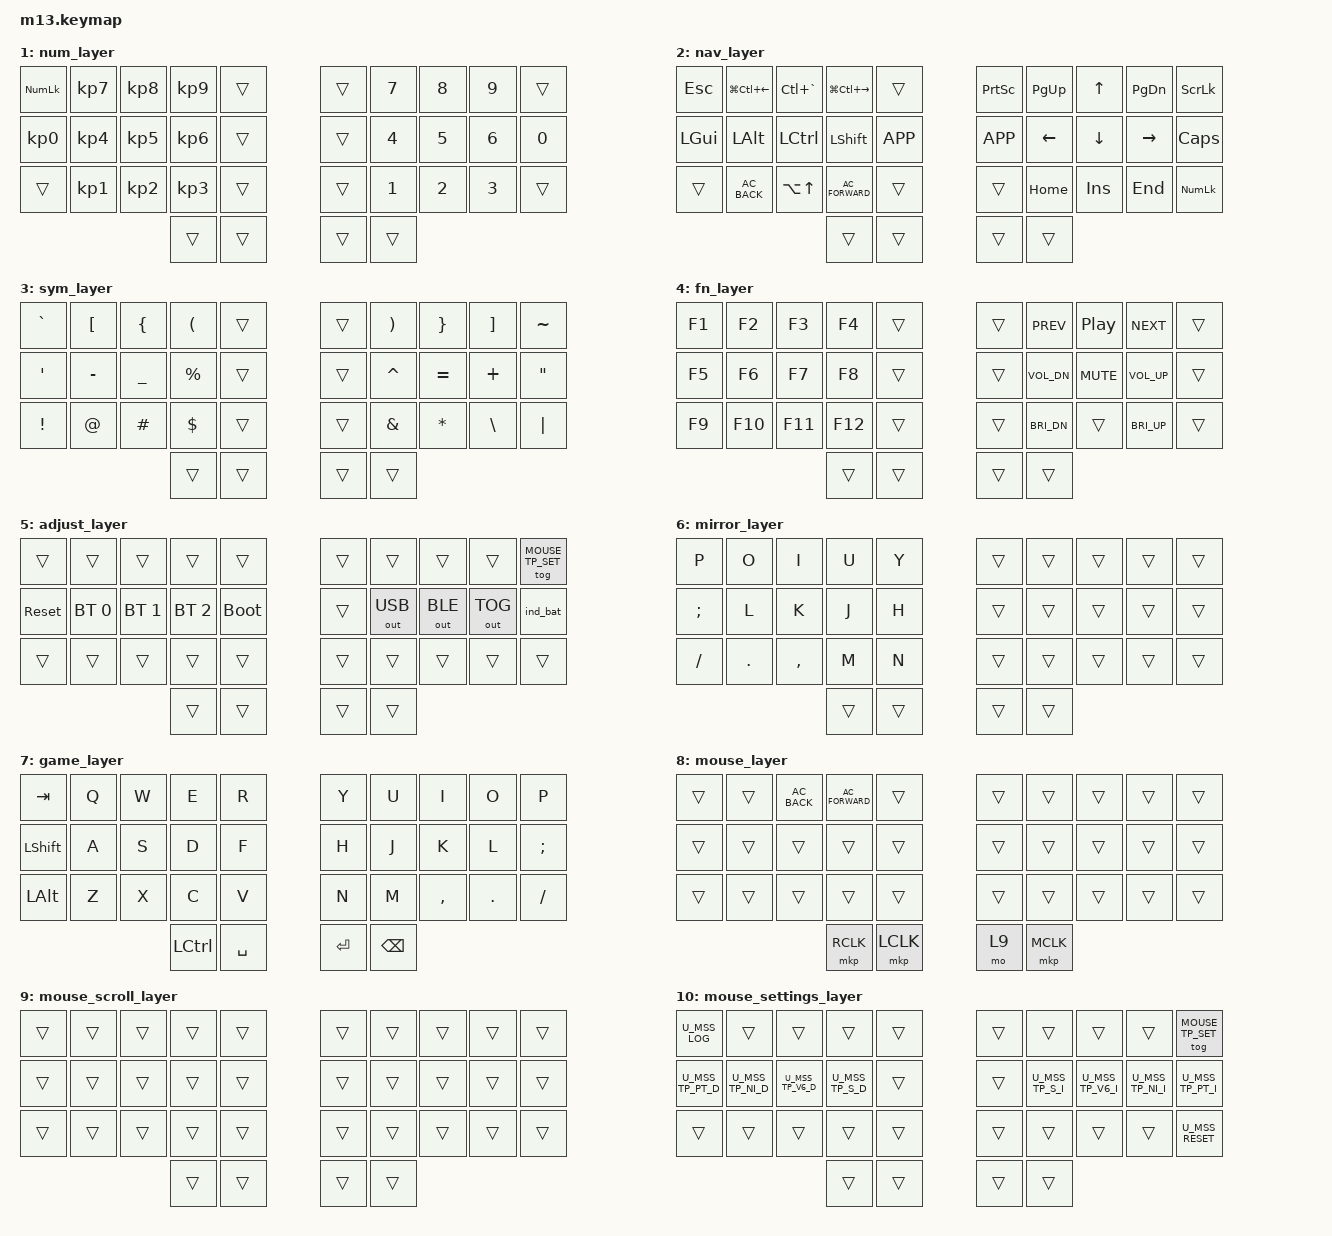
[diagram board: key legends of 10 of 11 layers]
#include <behaviors.dtsi>
#include <behaviors/status_led.dtsi>
#include <dt-bindings/zmk/keys.h>
#include <dt-bindings/zmk/bt.h>
#include <dt-bindings/zmk/outputs.h>
#include <dt-bindings/zmk/ext_power.h>


#define HAS_MOUSE_KEYS
#define HAS_MOUSE_TP

#ifdef HAS_MOUSE_KEYS
  #include <dt-bindings/zmk/mouse.h>
  #include <behaviors/mouse_keys.dtsi>
#endif  // HAS_MOUSE_KEYS

#ifdef HAS_MOUSE_TP
    #define MOUSE_TP 8
    #define MOUSE_TP_SCROLL 9 // not used
    #define MOUSE_TP_SET 10
    #define U_TOG_TP_SET &tog MOUSE_TP_SET
    #include <trackpoint/keymap.dtsi>

    #ifdef MOUSE_PS2_DT_PRESENT
    // Static trackpoint tuning (see the zmk-trackpoint README for all options)
    &mouse_ps2 {
        // How sensitive the TP is (Default: 128 / Max: 255)
        tp-sensitivity = <127>;

        // The maximum speed the TP will accelerate to (Default: 97 / Max: 255)
        tp-val6-upper-speed = <97>;

        // Sampling rate in hz. Allowed: 10,20,40,60,80,100,200
        sampling-rate = <100>;
    };
    #endif  // MOUSE_PS2_DT_PRESENT
#else
    #define MOUSE_TP 0
    #define U_TOG_TP_SET &none
#endif  // HAS_MOUSE_TP


#define HRML(k1,k2,k3,k4) &mt LGUI k1  &mt LALT k2  &mt LCTRL k3  &mt LSHFT k4
#define HRMR(k1,k2,k3,k4) &mt RSHFT k1  &mt RCTRL k2  &mt RALT k3  &mt RGUI k4
#define TERM &kp LC(GRAVE)
#define TASK_V &kp LG(TAB)
#define DESK_P &kp LG(LC(LEFT))
#define DESK_N &kp LG(LC(RIGHT))
#define COMBO(NAME, BINDINGS, KEYPOS, LAYERS) \
    combo_##NAME { \
        timeout-ms = <50>; \
        bindings = <BINDINGS>; \
        key-positions = <KEYPOS>; \
        layers = <LAYERS>; \
    };


&lt {
    flavor = "tap-preferred";
    tapping-term-ms = <150>;
    quick-tap-ms = <200>;
};

&mt {
    flavor = "balanced";
    tapping-term-ms = <150>;
    quick-tap-ms = <200>;
};


/ {
    //╭──────┬──────┬──────┬──────┬──────╮   ╭──────┬──────┬──────┬──────┬──────╮
    //│  0   │  1   │  2   │  3   │  4   │   │  5   │  6   │  7   │  8   │  9   │
    //├──────┼──────┼──────┼──────┼──────┼───┼──────┼──────┼──────┼──────┼──────┤
    //│  10  │  11  │  12  │  13  │  14  │   │  15  │  16  │  17  │  18  │  19  │
    //├──────┼──────┼──────┼──────┼──────┤   ├──────┼──────┼──────┼──────┼──────┤
    //│  20  │  21  │  22  │  23  │  24  │   │  25  │  26  │  27  │  28  │  29  │
    //╰──────┴──────┴──────┼──────┼──────┼───┼──────┼──────┼──────┴──────┴──────╯
    //                     |  30  |  31  |   |  32  |  33  |
    //                     ╰──────┴──────╯   ╰──────┴──────╯
    combos {
        compatible = "zmk,combos";
    // main
        COMBO(enter,              &kp RET,          12 13,        0)
        COMBO(backspace,          &kp BSPC,         11 12,        0)
        COMBO(delete,             &kp DEL,          11 13,        0)
        COMBO(fn_layer,           &mo 4,            30 24,        0)
        COMBO(go_up,              &kp LA(UP),        2  3,        8)
        COMBO(mouse_layer_lt,     &mo 8,            10 11,        0)
        COMBO(mouse_layer_rt,     &mo 8,            18 19,        0)
    // game
        COMBO(game,               &tog 7,           20 31,      0 7)
    // num
        COMBO(num_space_l,        &kp SPACE,        12 13,        1)
        COMBO(num_dot_l,          &kp DOT,          11 12,        1)
        COMBO(num_comma_l,        &kp COMMA,        11 13,        1)
        COMBO(num_space_r,        &kp SPACE,        16 17,        1)
        COMBO(num_dot_r,          &kp DOT,          17 18,        1)
        COMBO(num_comma_r,        &kp COMMA,        16 18,        1)
    // nav
        COMBO(nav_taskv,          TASK_V,            1  3,        2)
            // mirror
        COMBO(right_mirror,       &mo 6,             30 31,       0)
    // adjust
        COMBO(bluetooth_clear,    &bt BT_CLR,        10 14,       5)
    };


    conditional_layers {
        compatible = "zmk,conditional-layers";
        adjust_layer {
            if-layers = <2 3>;
            then-layer = <5>;
        };
    };


	chosen {
		zephyr,console = &cdc_acm_uart;
	};


    keymap {
        compatible = "zmk,keymap";

        // - 0
        default_layer {
            bindings = <
        //╭──────────┬──────────┬──────────┬──────────┬──────────╮   ╭──────────┬──────────┬──────────┬──────────┬──────────╮
        //│  Q       │  W       │  E       │  R       │  T       │   │  Y       │  U       │  I       │  O       │  P       │
            &kp Q      &lt 8 W    &kp E      &kp R      &kp T          &kp Y      &kp U      &kp I      &lt 8 O    &kp P
        //├──────────┼──────────┼──────────┼──────────┼──────────┤   ├──────────┼──────────┼──────────┼──────────┼──────────┤
        //│  A       │  S       │  D       │  F       │  G       │   │  H       │  J       │  K       │  L       │  ;       │
             HRML(A,        S,         D,         F)     &kp G          &kp H      HRMR(J,        K,         L,        SEMI)
        //├──────────┼──────────┼──────────┼──────────┼──────────┤   ├──────────┼──────────┼──────────┼──────────┼──────────┤
        //│  Z       │  X       │  C       │  V       │  B       │   │  N       │  M       │ , <      │ . >      │ / ?      │
            &kp Z      &kp X      &kp C      &kp V      &kp B          &kp N      &kp M      &kp COMMA  &kp DOT    &kp FSLH
        //╰──────────┴──────────┴──────────┼──────────┼──────────┤   ├──────────┼──────────┼──────────┴──────────┴──────────╯
                                            &lt 1 TAB  &lt 2 SPACE    &lt 3 RET  &lt 4 BSPC
        //                                 ╰──────────┴──────────╯   ╰──────────┴──────────╯
            >;
        };


        // - 1
        num_layer {
            bindings = <
        //╭──────────┬──────────┬──────────┬──────────┬──────────╮   ╭──────────┬──────────┬──────────┬──────────┬──────────╮
        //│  NLCK    │  7       │  8       │  9       │          │   │          │  7       │  8       │  9       │          │
            &kp KP_NUM &kp KP_N7  &kp KP_N8  &kp KP_N9  &trans         &trans     &kp N7     &kp N8     &kp N9     &trans
        //├──────────┼──────────┼──────────┼──────────┼──────────┤   ├──────────┼──────────┼──────────┼──────────┼──────────┤
        //│  0       │  4       │  5       │  6       │          │   │          │  4       │  5       │  6       │  0       │
            &kp KP_N0  &kp KP_N4  &kp KP_N5  &kp KP_N6  &trans         &trans     &kp N4     &kp N5     &kp N6     &kp N0
        //├──────────┼──────────┼──────────┼──────────┼──────────┤   ├──────────┼──────────┼──────────┼──────────┼──────────┤
        //│          │  1       │  2       │  3       │          │   │          │  1       │  2       │  3       │          │
            &trans     &kp KP_N1  &kp KP_N2  &kp KP_N3  &trans         &trans     &kp N1     &kp N2     &kp N3     &trans
        //╰──────────┴──────────┴──────────┼──────────┼──────────┤   ├──────────┼──────────┼──────────┴──────────┴──────────╯
                                             &trans     &trans         &trans     &trans
        //                                 ╰──────────┴──────────╯   ╰──────────┴──────────╯
            >;
        };


        // - 2
        nav_layer {
            bindings = <
        //╭──────────┬──────────┬──────────┬──────────┬──────────╮   ╭──────────┬──────────┬──────────┬──────────┬──────────╮
        //│ ESC      │ DESK <   │ TERMINAL │ DESK >   │          │   │ PRNT SCR │ PG_UP    │ UP       │ PG_DOWN  │ S_LCOK   │
            &kp ESC    DESK_P     TERM       DESK_N     &trans         &kp PSCRN  &kp PG_UP  &kp UP     &kp PG_DN  &kp SLCK
        //├──────────┼──────────┼──────────┼──────────┼──────────┤   ├──────────┼──────────┼──────────┼──────────┼──────────┤
        //│ GUI      │ ALT      │ CTRL     │ SHIFT    │ APP      │   │ APP      │ LEFT     │ DOWN     │ RIGHT    │ C_LOCK   │
            &kp LGUI   &kp LALT   &kp LCTRL  &kp LSHFT  &kp K_APP      &kp K_APP  &kp LEFT   &kp DOWN   &kp RIGHT  &kp CLCK
        //├──────────┼──────────┼──────────┼──────────┼──────────┤   ├──────────┼──────────┼──────────┼──────────┼──────────┤
        //│          │ BACK     │ UP       │ FORWARD  │          │   │          │ HOME     │ INSERT   │ END      │ N_LOCK   │
            &trans     &kp C_AC_BACK  &kp LA(UP)  &kp C_AC_FORWARD &trans  &trans &kp HOME   &kp INS    &kp END   &kp KP_NLCK
        //╰──────────┴──────────┴──────────┼──────────┼──────────┤   ├──────────┼──────────┼──────────┴──────────┴──────────╯
                                             &trans     &trans         &trans     &trans
        //                                 ╰──────────┴──────────╯   ╰──────────┴──────────╯
            >;
        };


        // - 3
        sym_layer {
            bindings = <
        //╭──────────┬──────────┬──────────┬──────────┬──────────╮   ╭──────────┬──────────┬──────────┬──────────┬──────────╮
        //│  `       │  [       │  {       │  (       │          │   │          │  )       │  }       │  ]       │  ~       │
            &kp GRAVE  &kp LBKT   &kp LBRC   &kp LPAR   &trans         &trans     &kp RPAR   &kp RBRC   &kp RBKT   &kp TILDE
        //├──────────┼──────────┼──────────┼──────────┼──────────┤   ├──────────┼──────────┼──────────┼──────────┼──────────┤
        //│  '       │  -       │  _       │  %       │          │   │          │  ^       │  =       │  +       │  "       │
            &kp SQT    &kp MINUS  &kp UNDER  &kp PRCNT  &trans         &trans     &kp CARET  &kp EQUAL  &kp PLUS   &kp DQT
        //├──────────┼──────────┼──────────┼──────────┼──────────┤   ├──────────┼──────────┼──────────┼──────────┼──────────┤
        //│  !       │  @       │  #       │  $       │          │   │          │  &       │  *       │  \       │  |       │
            &kp EXCL   &kp AT     &kp HASH   &kp DLLR   &trans         &trans     &kp AMPS   &kp ASTRK  &kp BSLH   &kp PIPE
        //╰──────────┴──────────┴──────────┼──────────┼──────────┤   ├──────────┼──────────┼──────────┴──────────┴──────────╯
                                             &trans     &trans         &trans     &trans
        //                                 ╰──────────┴──────────╯   ╰──────────┴──────────╯
            >;
        };


        // - 4
        fn_layer {
            bindings = <
        //╭──────────┬──────────┬──────────┬──────────┬──────────╮   ╭──────────┬──────────┬──────────┬──────────┬──────────╮
        //│ F1       │ F2       │ F3       │ F4       │          │   │          │ <<<      │ P\P      │ >>>      │          │
            &kp F1     &kp F2     &kp F3     &kp F4     &trans         &trans     &kp C_PREV &kp C_PP   &kp C_NEXT &trans
        //├──────────┼──────────┼──────────┼──────────┼──────────┤   ├──────────┼──────────┼──────────┼──────────┼──────────┤
        //│ F4       │ F5       │ F6       │ F8       │          │   │          │ VOL-     │ MUTE     │ VOL+     │          │
            &kp F5     &kp F6     &kp F7     &kp F8     &trans         &trans     &kp C_VOL_DN &kp C_MUTE &kp C_VOL_UP &trans
        //├──────────┼──────────┼──────────┼──────────┼──────────┤   ├──────────┼──────────┼──────────┼──────────┼──────────┤
        //│ F9       │ F10      │ F11      │ F12      │          │   │          │ BRI-     │          │ BRI+     │          │
            &kp F9     &kp F10    &kp F11    &kp F12    &trans         &trans     &kp C_BRI_DN &trans   &kp C_BRI_UP &trans
        //╰──────────┴──────────┴──────────┼──────────┼──────────┤   ├──────────┼──────────┼──────────┴──────────┴──────────╯
                                             &trans     &trans         &trans     &trans
        //                                 ╰──────────┴──────────╯   ╰──────────┴──────────╯
            >;
        };


        // - 5
        adjust_layer {
            bindings = <
        //╭──────────┬──────────┬──────────┬──────────┬──────────╮   ╭──────────┬──────────┬──────────┬──────────┬──────────╮
        //│          │          │          │          │          │   │          │          │          │          │ TP STNGS │
            &trans     &trans     &trans     &trans     &trans         &trans     &trans     &trans     &trans     U_TOG_TP_SET
        //├──────────┼──────────┼──────────┼──────────┼──────────┤   ├──────────┼──────────┼──────────┼──────────┼──────────┤
        //│ RESET    │ BT 0     │ BT 1     │ BT 2     │ BOOT     │   │          │ OUT USB  │ OUT BLE  │ OUT TOG  │  BAT     |
            &sys_reset &bt BT_SEL 0 &bt BT_SEL 1 &bt BT_SEL 2 &bootloader &trans &out OUT_USB &out OUT_BLE &out OUT_TOG &ind_bat
        //├──────────┼──────────┼──────────┼──────────┼──────────┤   ├──────────┼──────────┼──────────┼──────────┼──────────┤
        //│          │          │          │          │          │   │          │          │          │          │          │
            &trans     &trans     &trans     &trans     &trans         &trans     &trans     &trans     &trans     &trans
        //╰──────────┴──────────┴──────────┼──────────┼──────────┤   ├──────────┼──────────┼──────────┴──────────┴──────────╯
                                             &trans     &trans         &trans     &trans
        //                                 ╰──────────┴──────────╯   ╰──────────┴──────────╯
            >;
        };


        // - 6
        mirror_layer {
            bindings = <
        //╭──────────┬──────────┬──────────┬──────────┬──────────╮   ╭──────────┬──────────┬──────────┬──────────┬──────────╮
        //│  P       │  O       │  I       │  U       │  Y       │   │          │          │          │          │          │
            &kp P      &kp O      &kp I      &kp U      &kp Y          &trans     &trans     &trans     &trans     &trans
        //├──────────┼──────────┼──────────┼──────────┼──────────┤   ├──────────┼──────────┼──────────┼──────────┼──────────┤
        //│  ;       │  L       │  K       │  J       │  H       │   │          │          │          │          │          │
            &kp SEMI   &kp L      &kp K      &kp J      &kp H          &trans     &trans     &trans     &trans     &trans
        //├──────────┼──────────┼──────────┼──────────┼──────────┤   ├──────────┼──────────┼──────────┼──────────┼──────────┤
        //│  / ?     │ . >      │ , <      │  M       │  N       │   │          │          │          │          │          │
            &kp FSLH   &kp DOT    &kp COMMA  &kp M      &kp N          &trans     &trans     &trans     &trans     &trans
        //╰──────────┴──────────┴──────────┼──────────┼──────────┤   ├──────────┼──────────┼──────────┴──────────┴──────────╯
                                             &trans     &trans         &trans     &trans
        //                                 ╰──────────┴──────────╯   ╰──────────┴──────────╯
            >;
        };


        // - 7
        game_layer {
            bindings = <
        //╭──────────┬──────────┬──────────┬──────────┬──────────╮   ╭──────────┬──────────┬──────────┬──────────┬──────────╮
        //│  TAB     │  Q       │  W       │  E       │  R       │   │  Y       │  U       │  I       │  O       │  P       │
            &kp TAB    &kp Q      &kp W      &kp E      &kp R          &kp Y      &kp U      &kp I      &kp O      &kp P
        //├──────────┼──────────┼──────────┼──────────┼──────────┤   ├──────────┼──────────┼──────────┼──────────┼──────────┤
        //│  SHIFT   │  A       │  S       │  D       │  F       │   │  H       │  J       │  K       │  L       │  ;       │
            &kp LSHFT  &kp A      &kp S      &kp D      &kp F          &kp H      &kp J      &kp K      &kp L      &kp SEMI
        //├──────────┼──────────┼──────────┼──────────┼──────────┤   ├──────────┼──────────┼──────────┼──────────┼──────────┤
        //│  ALT     │  Z       │  X       │  C       │  V       │   │  N       │  M       │  ,       │  .       │  /       │
            &kp LALT   &kp Z      &kp X      &kp C      &kp V          &kp N      &kp M      &kp COMMA  &kp DOT    &kp FSLH
        //╰──────────┴──────────┴──────────┼──────────┼──────────┤   ├──────────┼──────────┼──────────┴──────────┴──────────╯
                                             &kp LCTRL  &kp SPACE      &kp RET    &kp BSPC
        //                                 ╰──────────┴──────────╯   ╰──────────┴──────────╯
            >;
        };


        #ifdef HAS_MOUSE_TP
        // - 8
        mouse_layer {
            bindings = <
        //╭──────────┬──────────┬──────────┬──────────┬──────────╮   ╭──────────┬──────────┬──────────┬──────────┬──────────╮
            &trans     &trans  &kp C_AC_BACK &kp C_AC_FORWARD &trans   &trans     &trans     &trans     &trans     &trans
        //├──────────┼──────────┼──────────┼──────────┼──────────┤   ├──────────┼──────────┼──────────┼──────────┼──────────┤
            &trans     &trans     &trans     &trans      &trans        &trans     &trans     &trans     &trans     &trans
        //├──────────┼──────────┼──────────┼──────────┼──────────┤   ├──────────┼──────────┼──────────┼──────────┼──────────┤
            &trans     &trans     &trans     &trans     &trans         &trans     &trans     &trans     &trans     &trans
        //╰──────────┴──────────┴──────────┼──────────┼──────────┤   ├──────────┼──────────┼──────────┴──────────┴──────────╯
                                             &mkp RCLK  &mkp LCLK      &mo 9      &mkp MCLK
        //                                 ╰──────────┴──────────╯   ╰──────────┴──────────╯
            >;
        };


        // - 9
        mouse_scroll_layer {
            bindings = <
        //╭──────────┬──────────┬──────────┬──────────┬──────────╮   ╭──────────┬──────────┬──────────┬──────────┬──────────╮
            &trans     &trans     &trans     &trans     &trans         &trans     &trans     &trans     &trans     &trans
        //├──────────┼──────────┼──────────┼──────────┼──────────┤   ├──────────┼──────────┼──────────┼──────────┼──────────┤
            &trans     &trans     &trans     &trans     &trans         &trans     &trans     &trans     &trans     &trans
        //├──────────┼──────────┼──────────┼──────────┼──────────┤   ├──────────┼──────────┼──────────┼──────────┼──────────┤
            &trans     &trans     &trans     &trans     &trans         &trans     &trans     &trans     &trans     &trans
        //╰──────────┴──────────┴──────────┼──────────┼──────────┤   ├──────────┼──────────┼──────────┴──────────┴──────────╯
                                             &trans     &trans         &trans     &trans
        //                                 ╰──────────┴──────────╯   ╰──────────┴──────────╯
            >;
        };


        // - 10
        mouse_settings_layer {
            bindings = <
        //╭──────────┬──────────┬──────────┬──────────┬──────────╮   ╭──────────┬──────────┬──────────┬──────────┬──────────╮
        U_MSS_LOG      &trans     &trans     &trans     &trans         &trans     &trans     &trans     &trans     U_TOG_TP_SET
        //├──────────┼──────────┼──────────┼──────────┼──────────┤   ├──────────┼──────────┼──────────┼──────────┼──────────┤
        U_MSS_TP_PT_D  U_MSS_TP_NI_D  U_MSS_TP_V6_D  U_MSS_TP_S_D  &trans  &trans  U_MSS_TP_S_I  U_MSS_TP_V6_I  U_MSS_TP_NI_I  U_MSS_TP_PT_I
        //├──────────┼──────────┼──────────┼──────────┼──────────┤   ├──────────┼──────────┼──────────┼──────────┼──────────┤
            &trans     &trans     &trans     &trans     &trans         &trans     &trans     &trans     &trans     U_MSS_RESET
        //╰──────────┴──────────┴──────────┼──────────┼──────────┤   ├──────────┼──────────┼──────────┴──────────┴──────────╯
                                             &trans     &trans         &trans     &trans
        //                                 ╰──────────┴──────────╯   ╰──────────┴──────────╯
            >;
        };
        #endif
    };
};

// Allow USB logging
&usbd {
	status = "okay";
	cdc_acm_uart: cdc_acm_uart {
		compatible = "zephyr,cdc-acm-uart";
		label = "CDC_ACM_0";
	};
};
